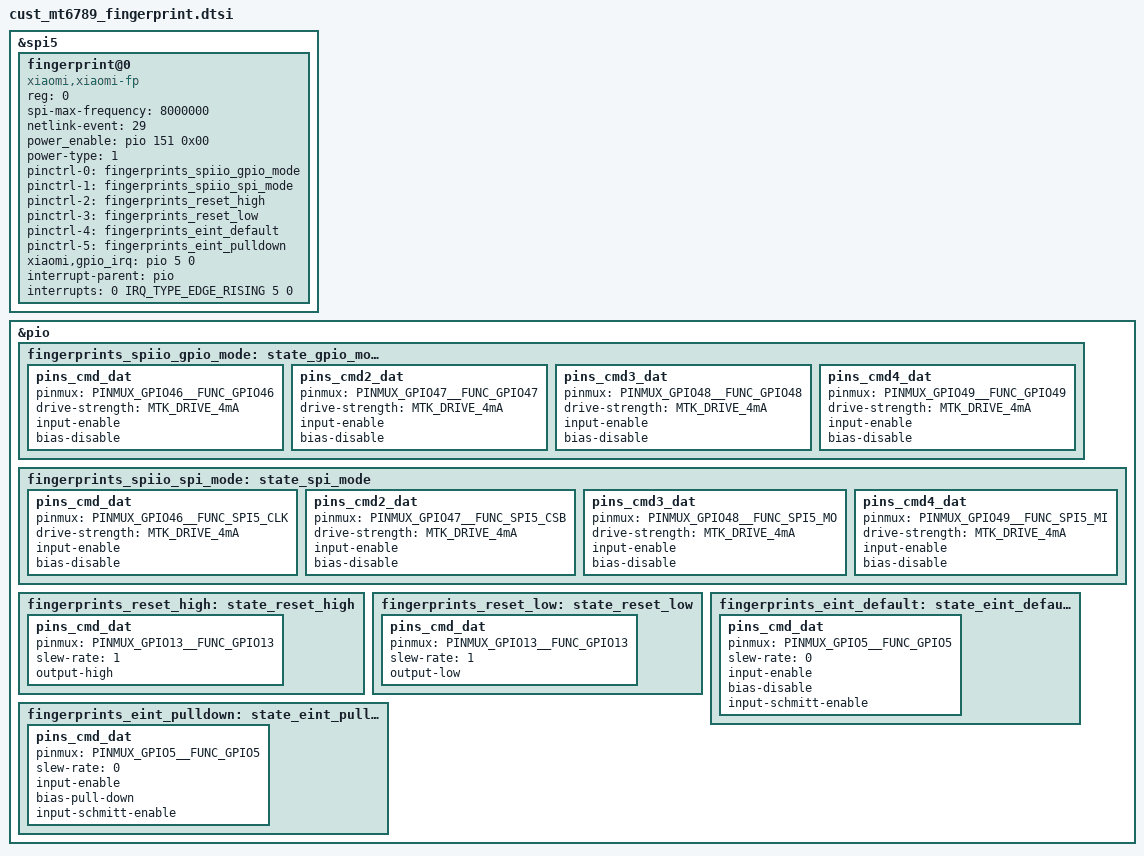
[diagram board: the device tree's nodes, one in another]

// SPDX-License-Identifier: (GPL-2.0 OR MIT)
/*
 * Copyright (C) 2023 MediaTek Inc.
 */
/* fingerprint start */
&spi5 {
	#address-cells = <1>;
	#size-cells = <0>;
	fingerprint@0 {
		compatible = "xiaomi,xiaomi-fp";
		reg = <0>;
		spi-max-frequency = <8000000>;
		netlink-event = <29>;
		power_enable = <&pio 151 0x00>;
		power-type = <1>;
		pinctrl-names = "spiio_gpio_mode", "spiio_spi_mode", "reset_high", "reset_low", "eint_default", "eint_pulldown";
		pinctrl-0 = <&fingerprints_spiio_gpio_mode>;
		pinctrl-1 = <&fingerprints_spiio_spi_mode>;
		pinctrl-2 = <&fingerprints_reset_high>;
		pinctrl-3 = <&fingerprints_reset_low>;
		pinctrl-4 = <&fingerprints_eint_default>;
		pinctrl-5 = <&fingerprints_eint_pulldown>;
		xiaomi,gpio_irq = <&pio 5 0>;
		interrupt-parent = <&pio>;
		interrupts = <0 IRQ_TYPE_EDGE_RISING 5 0>;
		status = "okay";
	};
};
&pio {
	fingerprints_spiio_gpio_mode: state_gpio_mode {
		pins_cmd_dat {
			pinmux = <PINMUX_GPIO46__FUNC_GPIO46>;
			drive-strength = <MTK_DRIVE_4mA>;
			input-enable;
			bias-disable;
		};
		pins_cmd2_dat {
			pinmux = <PINMUX_GPIO47__FUNC_GPIO47>;
			drive-strength = <MTK_DRIVE_4mA>;
			input-enable;
			bias-disable;
		};
		pins_cmd3_dat {
			pinmux = <PINMUX_GPIO48__FUNC_GPIO48>;
			drive-strength = <MTK_DRIVE_4mA>;
			input-enable;
			bias-disable;
		};
		pins_cmd4_dat {
			pinmux = <PINMUX_GPIO49__FUNC_GPIO49>;
			drive-strength = <MTK_DRIVE_4mA>;
			input-enable;
			bias-disable;
		};
	};
	fingerprints_spiio_spi_mode: state_spi_mode {
		pins_cmd_dat {
			pinmux = <PINMUX_GPIO46__FUNC_SPI5_CLK>;
			drive-strength = <MTK_DRIVE_4mA>;
			input-enable;
			bias-disable;
		};
		pins_cmd2_dat {
			pinmux = <PINMUX_GPIO47__FUNC_SPI5_CSB>;
			drive-strength = <MTK_DRIVE_4mA>;
			input-enable;
			bias-disable;
		};
		pins_cmd3_dat {
			pinmux = <PINMUX_GPIO48__FUNC_SPI5_MO>;
			drive-strength = <MTK_DRIVE_4mA>;
			input-enable;
			bias-disable;
		};
		pins_cmd4_dat {
			pinmux = <PINMUX_GPIO49__FUNC_SPI5_MI>;
			drive-strength = <MTK_DRIVE_4mA>;
			input-enable;
			bias-disable;
		};
	};
	fingerprints_reset_high: state_reset_high {
		pins_cmd_dat {
			pinmux = <PINMUX_GPIO13__FUNC_GPIO13>;
			slew-rate = <1>;
			output-high;
		};
	};
	fingerprints_reset_low: state_reset_low {
		pins_cmd_dat {
			pinmux = <PINMUX_GPIO13__FUNC_GPIO13>;
			slew-rate = <1>;
			output-low;
		};
	};
	fingerprints_eint_default: state_eint_default {
		pins_cmd_dat {
			pinmux = <PINMUX_GPIO5__FUNC_GPIO5>;
			slew-rate = <0>;
			input-enable;
			bias-disable;
			input-schmitt-enable;
		};
	};
	fingerprints_eint_pulldown: state_eint_pulldown {
		pins_cmd_dat {
			pinmux = <PINMUX_GPIO5__FUNC_GPIO5>;
			slew-rate = <0>;
			input-enable;
			bias-pull-down;
			input-schmitt-enable;
		};
	};
};
/* fingerprint end */
